# HK32F030xMxxA register map
Vendor: HKMicroChip Ltd.; Series: HK32F030xMxxA; File version: 0.9
CPU: CM0 r0p0, little endian, no MPU, no FPU, 3 interrupt priority bits
Registers are 32-bit, read-write, reset 0x0 unless marked. A register's access mark holds for its fields unless they carry their own. Offsets are from the block's base; [hi:lo] are bit positions; {n}, {i} and the like mark numbered series.

## PWR
Base 0x40007000
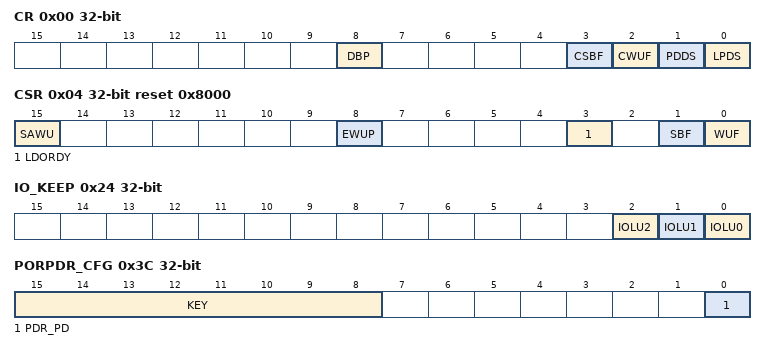
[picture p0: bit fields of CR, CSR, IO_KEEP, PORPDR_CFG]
0x00 CR
  [8] DBP — Disable backup protection
  [3] CSBF — Clear Standby flag
  [2] CWUF — Clear wakeup flag
  [1] PDDS — Power down deepsleep
  [0] LPDS — Low power deepsleep
0x04 CSR access per field reset 0x8000
  [15] SAWU rw — Standby auto wakeup
  [8] EWUP rw — Enable WKUP pin
  [3] LDORDY ro — LDO status flag
  [1] SBF ro — Standby flag
  [0] WUF ro — Wakeup flag
0x24 IO_KEEP
  [2] IOLU2 — IO Latch up 0
  [1] IOLU1 — IO Latch up 1
  [0] IOLU0 — IO Latch up 2
0x34 WUP_POL reset 0x8000
  [0] WUPOL — Wakeup pin1 polarity selection
0x3C PORPDR_CFG access per field
  [15:8] KEY wo — Key to unlock PDR_PD
  [0] PDR_PD rw — PDR Power down
0x9C STBAWU reset 0x7D
  [15:0] TIME_CNT — Timer counter
0xA0 SBKP0
  [15:0] SBKP0 — Standby backup 0 register
0xA4 SBKP1
  [15:0] SBKP1 — Standby backup 1 register

## SYSCFG
Base 0x40010000
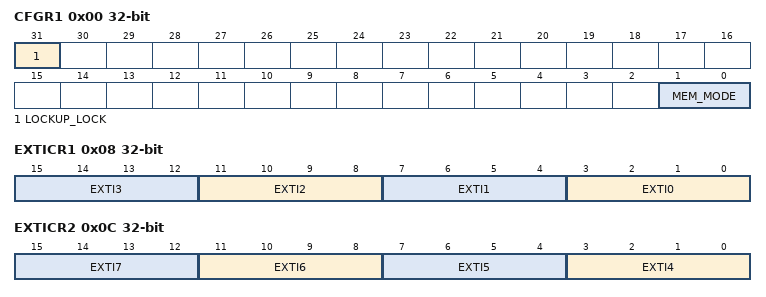
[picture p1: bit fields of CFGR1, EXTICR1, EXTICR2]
0x00 CFGR1
  [31] LOCKUP_LOCK — LOCKUP bit enable
  [1:0] MEM_MODE — Memory mapping selection
0x08 EXTICR1
  [4n+3:4n] EXTI{n} (n=0..3) — EXTI x configuration bits
0x0C EXTICR2
  [4n-13:4n-16] EXTI{n} (n=4..7) — EXTI x configuration bits

## GPIOA
Base 0x48000000
Same registers: GPIOB 0x48000400, GPIOC 0x48000800, GPIOD 0x48000C00
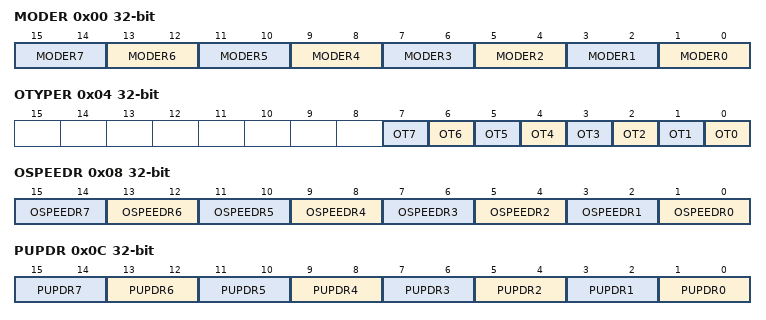
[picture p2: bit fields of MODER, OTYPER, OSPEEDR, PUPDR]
0x00 MODER
  [2n+1:2n] MODER{n} (n=0..7) — Port x pin y mode configuration bits
0x04 OTYPER
  [n] OT{n} (n=0..7) — Port x pin y output type configuration bits
0x08 OSPEEDR
  [2n+1:2n] OSPEEDR{n} (n=0..7) — Port x pin y output speed configuration bits
0x0C PUPDR
  [2n+1:2n] PUPDR{n} (n=0..7) — Port x pin y pull-up/down configuration bits
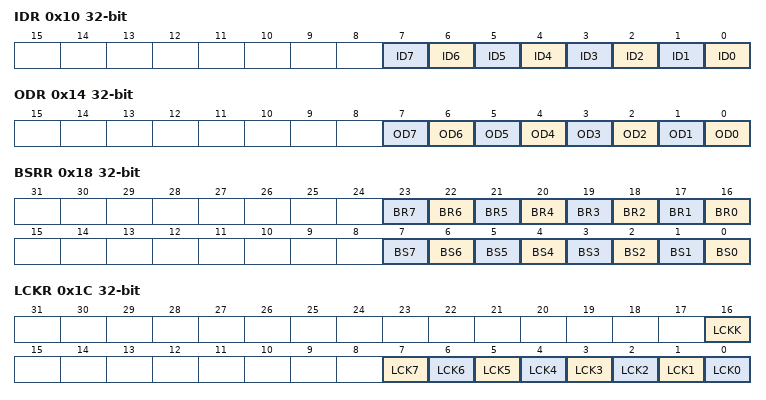
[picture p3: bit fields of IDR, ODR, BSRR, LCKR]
0x10 IDR ro
  [n] ID{n} (n=0..7) — Port x pin y input data
0x14 ODR
  [n] OD{n} (n=0..7) — Port x pin y output data
0x18 BSRR wo
  [n+16] BR{n} (n=0..7) — Port x reset bit y
  [n] BS{n} (n=0..7) — Port x set bit y
0x1C LCKR
  [16] LCKK — Lock key
  [n] LCK{n} (n=0..7) — Port x pin y lock bit y
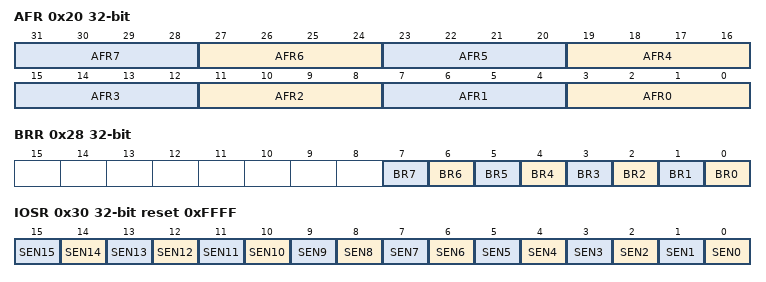
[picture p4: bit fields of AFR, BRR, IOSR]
0x20 AFR
  [4n+3:4n] AFR{n} (n=0..7) — Alternate function selection bits for port x pin y
0x28 BRR wo
  [n] BR{n} (n=0..7) — Port x pin y reset bit y
0x30 IOSR reset 0xFFFF
  [n] SEN{n} (n=0..15) — Port x pin y Schmitt switch

## IOMUX
Base 0x40017C00
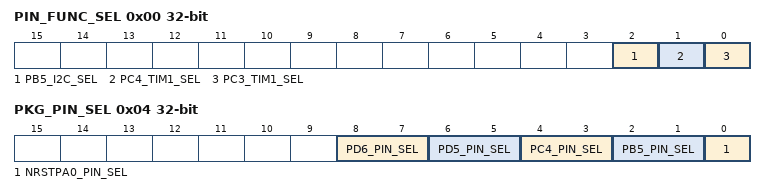
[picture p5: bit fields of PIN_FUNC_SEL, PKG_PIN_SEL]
0x00 PIN_FUNC_SEL
  [2] PB5_I2C_SEL — Pin functional selection for PB5
  [1] PC4_TIM1_SEL — Pin functional selection for PC4
  [0] PC3_TIM1_SEL — Pin functional selection for PC3
0x04 PKG_PIN_SEL
  [8:7] PD6_PIN_SEL — Pin MUX for PD6
  [6:5] PD5_PIN_SEL — Pin MUX for PD5
  [4:3] PC4_PIN_SEL — Pin MUX for PC4
  [2:1] PB5_PIN_SEL — Pin MUX for PB5
  [0] NRSTPA0_PIN_SEL — Pin MUX for NRST
0x08 NRST_PIN_KEY
  [15:0] NRST_PIN_KEY — The key of pin NRST change to PA0
0x0C NRST_PA0_SEL
  [0] NRST_PA0_SEL — Pin Functional Selection for NRST/PA0
0x10 TIM2_CH0_IN_SEL
  [1:0] TIM2_CH0_IN_SEL — Source Selection of TIM2 Channel1

## EXTI
Base 0x40010400
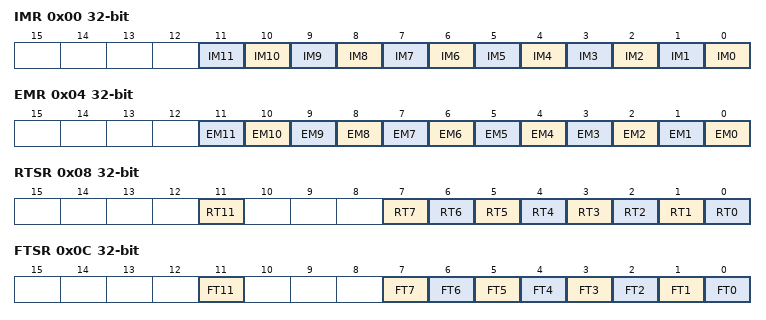
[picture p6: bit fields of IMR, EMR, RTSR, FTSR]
0x00 IMR
  [n] IM{n} (n=0..11) — Interrupt mask on line x
0x04 EMR
  [n] EM{n} (n=0..11) — Event mask on line x
0x08 RTSR
  [11] RT11 — Rising trigger event configuration bit of line 11
  [n] RT{n} (n=0..7) — Rising trigger event configuration bit of line x
0x0C FTSR
  [11] FT11 — Falling trigger event configuration bit of line 11
  [n] FT{n} (n=0..7) — Falling trigger event configuration bit of line x
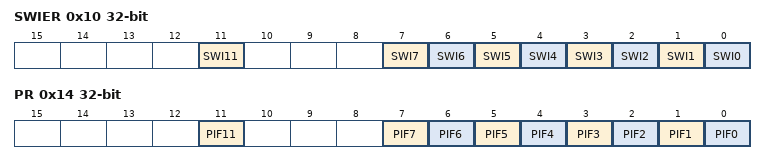
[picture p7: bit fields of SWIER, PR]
0x10 SWIER
  [11] SWI11 — Software interrupt on line 11
  [n] SWI{n} (n=0..7) — Software interrupt on line x
0x14 PR
  [11] PIF11 — Pending interrupt flag on line 11
  [n] PIF{n} (n=0..7) — Pending interrupt flag on line x

## ADC
Base 0x40012400
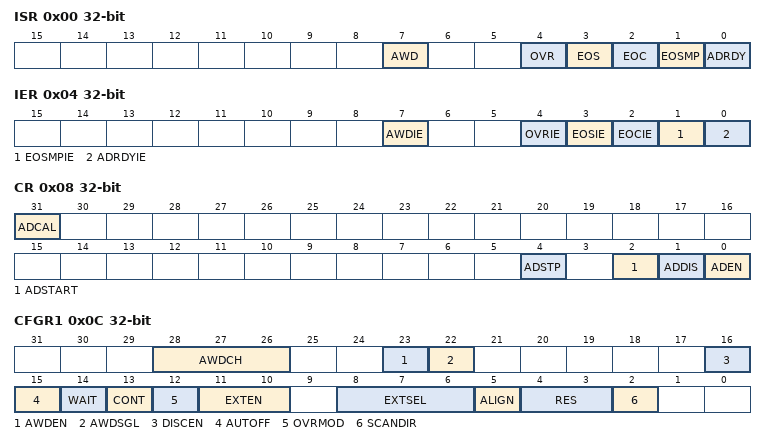
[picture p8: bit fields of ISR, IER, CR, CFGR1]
0x00 ISR
  [7] AWD — End of calibration flag
  [4] OVR — ADC overrun
  [3] EOS — End of sequence flag
  [2] EOC — End of conversion flag
  [1] EOSMP — End of sampling flag
  [0] ADRDY — ADC ready
0x04 IER
  [7] AWDIE — Analog watchdog interrupt enable
  [4] OVRIE — Overrun interrupt enable
  [3] EOSIE — End of conversion sequence interrupt enable
  [2] EOCIE — End of conversion interrupt enable
  [1] EOSMPIE — End of sampling flag interrupt enable
  [0] ADRDYIE — ADC ready interrupt enable
0x08 CR
  [31] ADCAL — ADC calibration
  [4] ADSTP — ADC stop conversion command
  [2] ADSTART — ADC start conversion command
  [1] ADDIS — ADC disable command
  [0] ADEN — ADC enable command
0x0C CFGR1
  [28:26] AWDCH — Analog watchdog channel selection
  [23] AWDEN — Analog watchdog enable
  [22] AWDSGL — Enable the watchdog on a single channel or on all channels
  [16] DISCEN — Discontinuous mode
  [15] AUTOFF — Auto-off mode
  [14] WAIT — Wait conversion mode
  [13] CONT — Single/continuous conversion mode
  [12] OVRMOD — Overrun management mode
  [11:10] EXTEN — External trigger enable and polarity selection
  [8:6] EXTSEL — External trigger selection
  [5] ALIGN — Data alignment
  [4:3] RES — Resolution
  [2] SCANDIR — Scan sequence direction
0x10 CFGR2
  [31:30] CKMODE — ADC clock mode
0x14 SMPR
  [2:0] SMP — Sampling time selection
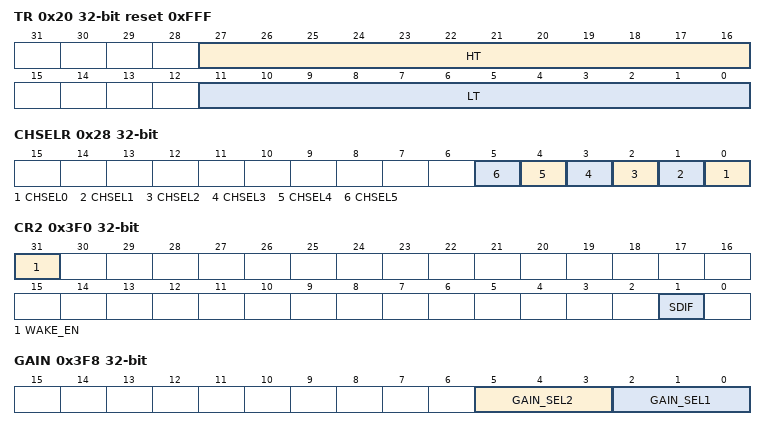
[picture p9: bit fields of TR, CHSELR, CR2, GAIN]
0x20 TR reset 0xFFF
  [27:16] HT — Analog watchdog higher threshold
  [11:0] LT — Analog watchdog lower threshold
0x28 CHSELR
  [n] CHSEL{n} (n=0..5) — Channel-x selection
0x40 DR ro
  [15:0] DATA — Converted data
0x308 CCR
  [22] VREFEN — VREFINT enable
{0x3C0+4i} DR{i} ro (i=0..5)
  [11:0] DRx — Channel x latest converted data
0x3F0 CR2
  [31] WAKE_EN — AWD function enable
  [1] SDIF — Differential input enable
0x3F8 GAIN
  [5:3] GAIN_SEL2 — Gain calibration factor 2 selection
  [2:0] GAIN_SEL1 — Gain calibration factor 1 selection
